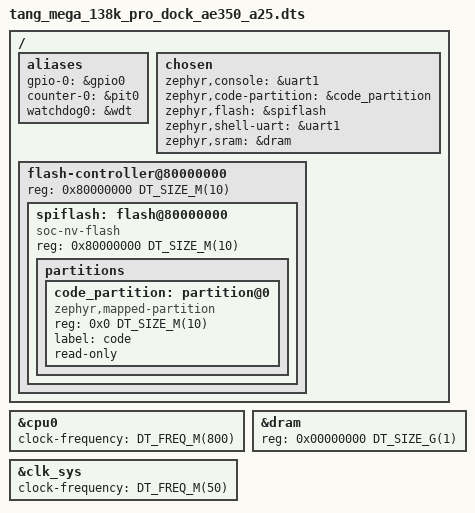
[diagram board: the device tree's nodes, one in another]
/*
 * SPDX-FileCopyrightText: Copyright (c) 2026 TOKITA Hiroshi
 * SPDX-License-Identifier: Apache-2.0
 */

#include <riscv/andes/andes_v5_ae350_a25.dtsi>
#include <freq.h>

/delete-node/ &spi0;

/ {
	aliases {
		gpio-0 = &gpio0;
		counter-0 = &pit0;
		watchdog0 = &wdt;
	};

	chosen {
		zephyr,console = &uart1;
		zephyr,code-partition = &code_partition;
		zephyr,flash = &spiflash;
		zephyr,shell-uart = &uart1;
		zephyr,sram = &dram;
	};

	flash-controller@80000000 {
		reg = <0x80000000 DT_SIZE_M(10)>;
		ranges;
		#address-cells = <1>;
		#size-cells = <1>;

		spiflash: flash@80000000 {
			compatible = "soc-nv-flash";
			reg = <0x80000000 DT_SIZE_M(10)>;
			ranges = <0x0 0x80000000 DT_SIZE_M(10)>;
			#address-cells = <1>;
			#size-cells = <1>;

			partitions {
				ranges;
				#address-cells = <1>;
				#size-cells = <1>;

				code_partition: partition@0 {
					compatible = "zephyr,mapped-partition";
					reg = <0x0 DT_SIZE_M(10)>;
					label = "code";
					read-only;
				};
			};
		};
	};
};

&cpu0 {
	clock-frequency = <DT_FREQ_M(800)>;
};

&dram {
	reg = <0x00000000 DT_SIZE_G(1)>;
};

&clk_sys {
	clock-frequency = <DT_FREQ_M(50)>;
};
